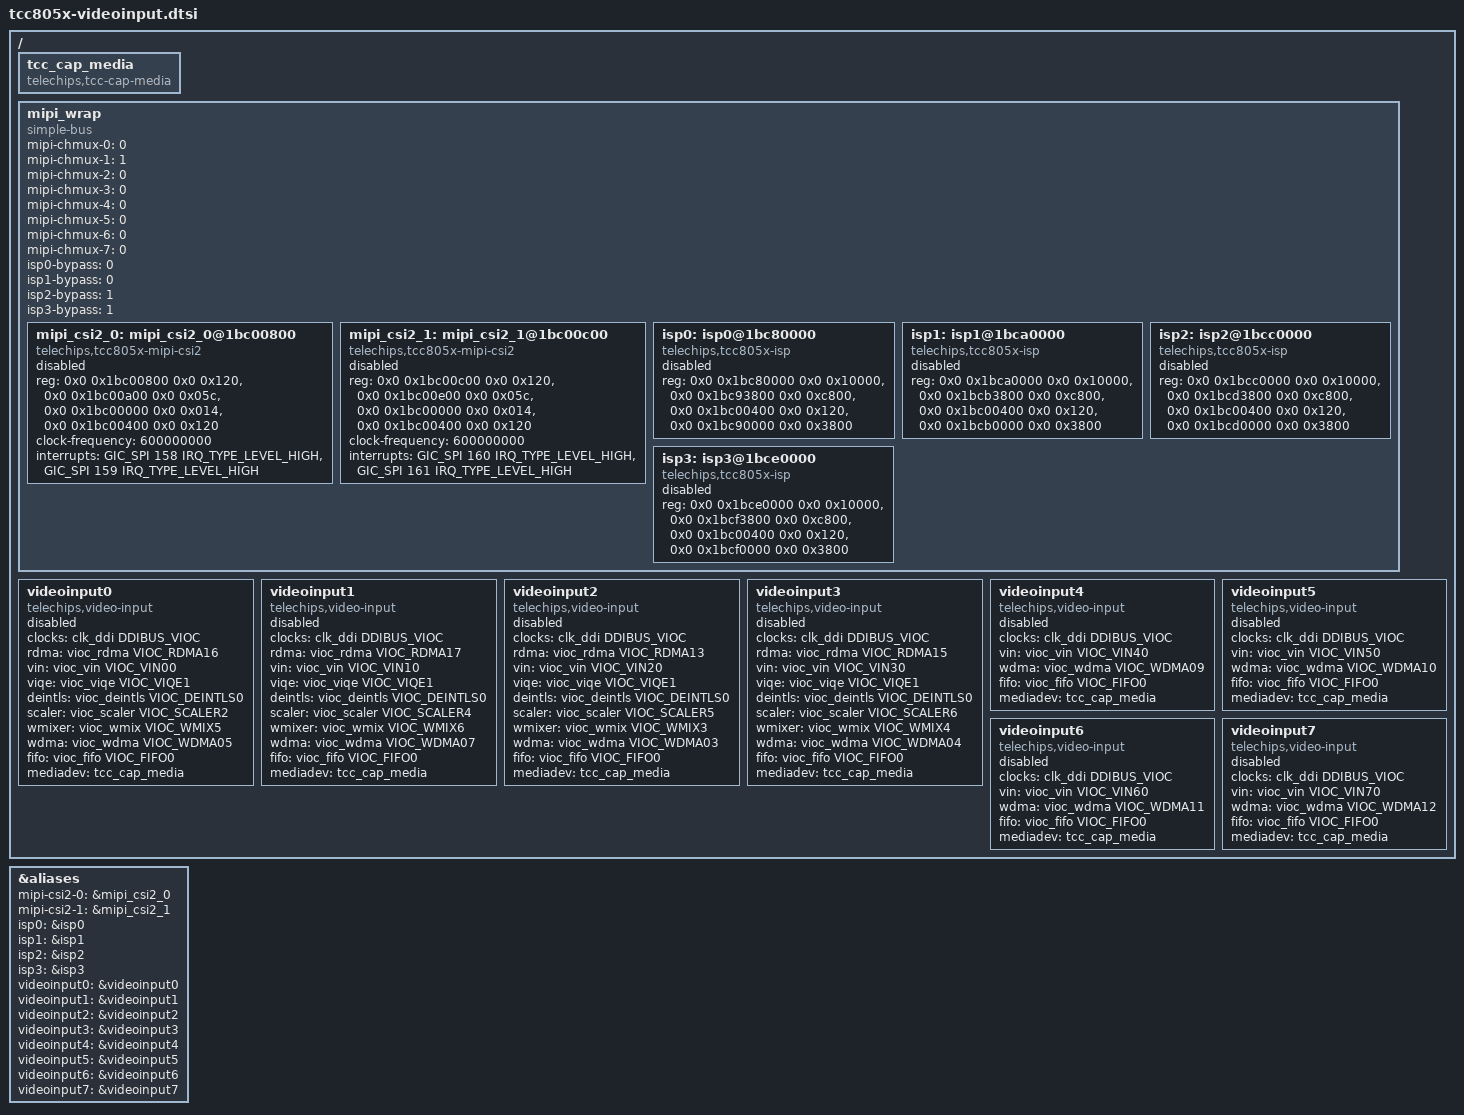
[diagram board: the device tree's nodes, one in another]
// SPDX-License-Identifier: (GPL-2.0-or-later OR MIT)
/*
 * Copyright (C) Telechips Inc.
 */

&aliases {
	mipi-csi2-0 = &mipi_csi2_0;
	mipi-csi2-1 = &mipi_csi2_1;
	isp0 = &isp0;
	isp1 = &isp1;
	isp2 = &isp2;
	isp3 = &isp3;
	videoinput0 = &videoinput0;
	videoinput1 = &videoinput1;
	videoinput2 = &videoinput2;
	videoinput3 = &videoinput3;
	videoinput4 = &videoinput4;
	videoinput5 = &videoinput5;
	videoinput6 = &videoinput6;
	videoinput7 = &videoinput7;
};

/ {
	tcc_cap_media: tcc_cap_media {
		compatible = "telechips,tcc-cap-media";
	};

	mipi_wrap: mipi_wrap {
		#address-cells = <2>;
		#size-cells = <2>;
		compatible = "simple-bus";
		ranges;

		/*
		 * If MIPI0 ,1 are used in main & sub core,
		 * properties below must be same
		 */

		/*
		 * 0: select output of MIPI0
		 * 1: select output of MIPI1
		 */
		mipi-chmux-0 = <0>;
		mipi-chmux-1 = <1>;
		mipi-chmux-2 = <0>;
		mipi-chmux-3 = <0>;

		/*
		 * 0: select output of MIPI1
		 * 1: select output of MIPI0
		 */
		mipi-chmux-4 = <0>;
		mipi-chmux-5 = <0>;
		mipi-chmux-6 = <0>;
		mipi-chmux-7 = <0>;

		/*
		 * 1: bypass isp
		 * 0: use isp
		 */
		isp0-bypass = <0>;
		isp1-bypass = <0>;
		isp2-bypass = <1>;
		isp3-bypass = <1>;

		mipi_csi2_0: mipi_csi2_0@1bc00800 {
			compatible = "telechips,tcc805x-mipi-csi2";
			status = "disabled";

			reg = <0x0 0x1bc00800 0x0 0x120>,
			      <0x0 0x1bc00a00 0x0 0x05c>,
			      <0x0 0x1bc00000 0x0 0x014>,
			      <0x0 0x1bc00400 0x0 0x120>;
			reg-names = "csi", "gdb", "ckc", "cfg";

			clock-frequency = <600000000>;

			interrupts = <GIC_SPI 158 IRQ_TYPE_LEVEL_HIGH>,
				     <GIC_SPI 159 IRQ_TYPE_LEVEL_HIGH>;
			interrupt-names = "csi", "gdb";
		};

		mipi_csi2_1: mipi_csi2_1@1bc00c00 {
			compatible = "telechips,tcc805x-mipi-csi2";
			status = "disabled";

			reg = <0x0 0x1bc00c00 0x0 0x120>,
			      <0x0 0x1bc00e00 0x0 0x05c>,
			      <0x0 0x1bc00000 0x0 0x014>,
			      <0x0 0x1bc00400 0x0 0x120>;
			reg-names = "csi", "gdb", "ckc", "cfg";

			clock-frequency = <600000000>;

			interrupts = <GIC_SPI 160 IRQ_TYPE_LEVEL_HIGH>,
				     <GIC_SPI 161 IRQ_TYPE_LEVEL_HIGH>;
			interrupt-names = "csi", "gdb";
		};

		isp0: isp0@1bc80000 {
			compatible = "telechips,tcc805x-isp";
			status = "disabled";
			reg = <0x0 0x1bc80000 0x0 0x10000>,
			      <0x0 0x1bc93800 0x0 0xc800>,
			      <0x0 0x1bc00400 0x0 0x120>,
			      <0x0 0x1bc90000 0x0 0x3800>;
			reg-names = "isp_base", "mem_base", "cfg_base",
				    "scene_data_base";
		};

		isp1: isp1@1bca0000 {
			compatible = "telechips,tcc805x-isp";
			status = "disabled";
			reg = <0x0 0x1bca0000 0x0 0x10000>,
			      <0x0 0x1bcb3800 0x0 0xc800>,
			      <0x0 0x1bc00400 0x0 0x120>,
			      <0x0 0x1bcb0000 0x0 0x3800>;
			reg-names = "isp_base", "mem_base", "cfg_base",
				    "scene_data_base";
		};

		isp2: isp2@1bcc0000 {
			compatible = "telechips,tcc805x-isp";
			status = "disabled";
			reg = <0x0 0x1bcc0000 0x0 0x10000>,
			      <0x0 0x1bcd3800 0x0 0xc800>,
			      <0x0 0x1bc00400 0x0 0x120>,
			      <0x0 0x1bcd0000 0x0 0x3800>;
			reg-names = "isp_base", "mem_base", "cfg_base",
				    "scene_data_base";
		};

		isp3: isp3@1bce0000 {
			compatible = "telechips,tcc805x-isp";
			status = "disabled";
			reg = <0x0 0x1bce0000 0x0 0x10000>,
			      <0x0 0x1bcf3800 0x0 0xc800>,
			      <0x0 0x1bc00400 0x0 0x120>,
			      <0x0 0x1bcf0000 0x0 0x3800>;
			reg-names = "isp_base", "mem_base", "cfg_base",
				    "scene_data_base";
		};
	};

	videoinput0: videoinput0 {
		compatible	= "telechips,video-input";
		status		= "disabled";
		clocks		= <&clk_ddi		DDIBUS_VIOC>;
		rdma		= <&vioc_rdma		VIOC_RDMA16>;
		vin		= <&vioc_vin		VIOC_VIN00>;
		viqe		= <&vioc_viqe		VIOC_VIQE1>;
		deintls		= <&vioc_deintls	VIOC_DEINTLS0>;
		scaler		= <&vioc_scaler		VIOC_SCALER2>;
		wmixer		= <&vioc_wmix		VIOC_WMIX5>;
		wdma		= <&vioc_wdma		VIOC_WDMA05>;
		fifo		= <&vioc_fifo		VIOC_FIFO0>;
		mediadev	= <&tcc_cap_media>;
	};

	videoinput1: videoinput1 {
		compatible	= "telechips,video-input";
		status		= "disabled";
		clocks		= <&clk_ddi		DDIBUS_VIOC>;
		rdma		= <&vioc_rdma		VIOC_RDMA17>;
		vin		= <&vioc_vin		VIOC_VIN10>;
		viqe		= <&vioc_viqe		VIOC_VIQE1>;
		deintls		= <&vioc_deintls	VIOC_DEINTLS0>;
		scaler		= <&vioc_scaler		VIOC_SCALER4>;
		wmixer		= <&vioc_wmix		VIOC_WMIX6>;
		wdma		= <&vioc_wdma		VIOC_WDMA07>;
		fifo		= <&vioc_fifo		VIOC_FIFO0>;
		mediadev	= <&tcc_cap_media>;
	};

	videoinput2: videoinput2 {
		compatible	= "telechips,video-input";
		status		= "disabled";
		clocks		= <&clk_ddi		DDIBUS_VIOC>;
		rdma		= <&vioc_rdma		VIOC_RDMA13>;
		vin		= <&vioc_vin		VIOC_VIN20>;
		viqe		= <&vioc_viqe		VIOC_VIQE1>;
		deintls		= <&vioc_deintls	VIOC_DEINTLS0>;
		scaler		= <&vioc_scaler		VIOC_SCALER5>;
		wmixer		= <&vioc_wmix		VIOC_WMIX3>;
		wdma		= <&vioc_wdma		VIOC_WDMA03>;
		fifo		= <&vioc_fifo		VIOC_FIFO0>;
		mediadev	= <&tcc_cap_media>;
	};

	videoinput3: videoinput3 {
		compatible	= "telechips,video-input";
		status		= "disabled";
		clocks		= <&clk_ddi		DDIBUS_VIOC>;
		rdma		= <&vioc_rdma		VIOC_RDMA15>;
		vin		= <&vioc_vin		VIOC_VIN30>;
		viqe		= <&vioc_viqe		VIOC_VIQE1>;
		deintls		= <&vioc_deintls	VIOC_DEINTLS0>;
		scaler		= <&vioc_scaler		VIOC_SCALER6>;
		wmixer		= <&vioc_wmix		VIOC_WMIX4>;
		wdma		= <&vioc_wdma		VIOC_WDMA04>;
		fifo		= <&vioc_fifo		VIOC_FIFO0>;
		mediadev	= <&tcc_cap_media>;
	};

	videoinput4: videoinput4 {
		compatible	= "telechips,video-input";
		status		= "disabled";
		clocks		= <&clk_ddi		DDIBUS_VIOC>;
		vin		= <&vioc_vin		VIOC_VIN40>;
		wdma		= <&vioc_wdma		VIOC_WDMA09>;
		fifo		= <&vioc_fifo		VIOC_FIFO0>;
		mediadev	= <&tcc_cap_media>;
	};

	videoinput5: videoinput5 {
		compatible	= "telechips,video-input";
		status		= "disabled";
		clocks		= <&clk_ddi		DDIBUS_VIOC>;
		vin		= <&vioc_vin		VIOC_VIN50>;
		wdma		= <&vioc_wdma		VIOC_WDMA10>;
		fifo		= <&vioc_fifo		VIOC_FIFO0>;
		mediadev	= <&tcc_cap_media>;
	};

	videoinput6: videoinput6 {
		compatible	= "telechips,video-input";
		status		= "disabled";
		clocks		= <&clk_ddi		DDIBUS_VIOC>;
		vin		= <&vioc_vin		VIOC_VIN60>;
		wdma		= <&vioc_wdma		VIOC_WDMA11>;
		fifo		= <&vioc_fifo		VIOC_FIFO0>;
		mediadev	= <&tcc_cap_media>;
	};

	videoinput7: videoinput7 {
		compatible	= "telechips,video-input";
		status		= "disabled";
		clocks		= <&clk_ddi		DDIBUS_VIOC>;
		vin		= <&vioc_vin		VIOC_VIN70>;
		wdma		= <&vioc_wdma		VIOC_WDMA12>;
		fifo		= <&vioc_fifo		VIOC_FIFO0>;
		mediadev	= <&tcc_cap_media>;
	};
};
